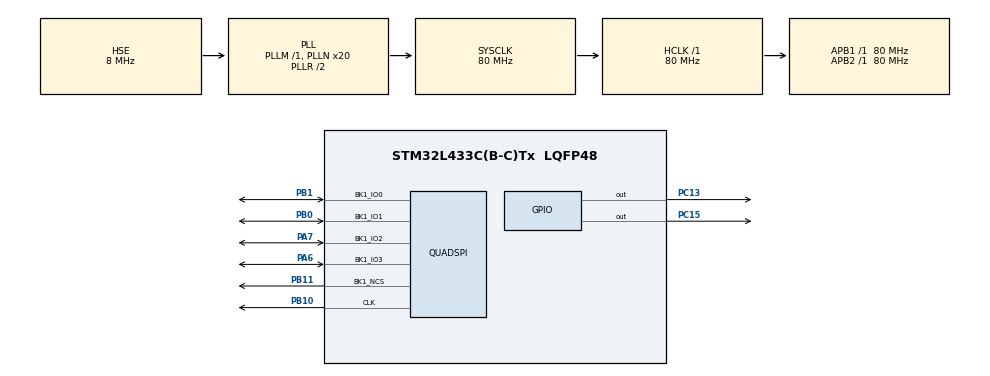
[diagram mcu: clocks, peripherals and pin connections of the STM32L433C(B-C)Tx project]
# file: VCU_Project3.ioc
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Mcu.Family=STM32L4
Mcu.Name=STM32L433C(B-C)Tx
Mcu.Package=LQFP48
NVIC.PriorityGroup=NVIC_PRIORITYGROUP_4
NVIC.QUADSPI_IRQn=true\:0\:0\:false\:false\:true
PA13\ (JTMS-SWDIO).Mode=Trace_Asynchronous_SW
PA13\ (JTMS-SWDIO).Signal=SYS_JTMS-SWDIO
PA14\ (JTCK-SWCLK).Mode=Trace_Asynchronous_SW
PA14\ (JTCK-SWCLK).Signal=SYS_JTCK-SWCLK
PA6.Mode=Single Bank 1
PA6.Signal=QUADSPI_BK1_IO3
PA7.Mode=Single Bank 1
PA7.Signal=QUADSPI_BK1_IO2
PB0.Mode=Single Bank 1
PB0.Signal=QUADSPI_BK1_IO1
PB1.Mode=Single Bank 1
PB1.Signal=QUADSPI_BK1_IO0
PB10.Mode=Single Bank 1
PB10.Signal=QUADSPI_CLK
PB11.Mode=Single Bank 1
PB11.Signal=QUADSPI_BK1_NCS
PB3\ (JTDO-TRACESWO).Mode=Trace_Asynchronous_SW
PB3\ (JTDO-TRACESWO).Signal=SYS_JTDO-SWO
PC13.Signal=GPIO_Output
PC15-OSC32_OUT\ (PC15).Signal=GPIO_Output
PH0-OSC_IN\ (PH0).Mode=HSE-External-Clock-Source
PH0-OSC_IN\ (PH0).Signal=RCC_OSC_IN
ProjectManager.HeapSize=0x200
ProjectManager.StackSize=0x400
ProjectManager.TargetToolchain=MDK-ARM V5
QUADSPI.ClockPrescaler=1
QUADSPI.FlashSize=23
RCC.ADCFreq_Value=32000000
RCC.AHBFreq_Value=80000000
RCC.APB1Freq_Value=80000000
RCC.APB1TimFreq_Value=80000000
RCC.APB2Freq_Value=80000000
RCC.APB2TimFreq_Value=80000000
RCC.CortexFreq_Value=80000000
RCC.HCLKFreq_Value=80000000
RCC.HSE_VALUE=8000000
RCC.HSI48_VALUE=48000000
RCC.HSI_VALUE=16000000
RCC.LSE_VALUE=32768
RCC.MSI_VALUE=4000000
RCC.PLLN=20
RCC.PLLSourceVirtual=RCC_PLLSOURCE_HSE
RCC.SYSCLKFreq_VALUE=80000000
RCC.SYSCLKSource=RCC_SYSCLKSOURCE_PLLCLK
RCC.USBFreq_Value=32000000
RCC.VCOOutputFreq_Value=160000000
VP_CRC_VS_CRC.Mode=CRC_Activate
VP_RNG_VS_RNG.Mode=RNG_Activate
board=VCU_Project3

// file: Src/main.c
/**
  ******************************************************************************
  * File Name          : main.c
  * Description        : Main program body
  ******************************************************************************
  *
  * COPYRIGHT(c) 2017 STMicroelectronics
  *
  * Redistribution and use in source and binary forms, with or without modification,
  * are permitted provided that the following conditions are met:
  *   1. Redistributions of source code must retain the above copyright notice,
  *      this list of conditions and the following disclaimer.
  *   2. Redistributions in binary form must reproduce the above copyright notice,
  *      this list of conditions and the following disclaimer in the documentation
  *      and/or other materials provided with the distribution.
  *   3. Neither the name of STMicroelectronics nor the names of its contributors
  *      may be used to endorse or promote products derived from this software
  *      without specific prior written permission.
  *
  * THIS SOFTWARE IS PROVIDED BY THE COPYRIGHT HOLDERS AND CONTRIBUTORS "AS IS"
  * AND ANY EXPRESS OR IMPLIED WARRANTIES, INCLUDING, BUT NOT LIMITED TO, THE
  * IMPLIED WARRANTIES OF MERCHANTABILITY AND FITNESS FOR A PARTICULAR PURPOSE ARE
  * DISCLAIMED. IN NO EVENT SHALL THE COPYRIGHT HOLDER OR CONTRIBUTORS BE LIABLE
  * FOR ANY DIRECT, INDIRECT, INCIDENTAL, SPECIAL, EXEMPLARY, OR CONSEQUENTIAL
  * DAMAGES (INCLUDING, BUT NOT LIMITED TO, PROCUREMENT OF SUBSTITUTE GOODS OR
  * SERVICES; LOSS OF USE, DATA, OR PROFITS; OR BUSINESS INTERRUPTION) HOWEVER
  * CAUSED AND ON ANY THEORY OF LIABILITY, WHETHER IN CONTRACT, STRICT LIABILITY,
  * OR TORT (INCLUDING NEGLIGENCE OR OTHERWISE) ARISING IN ANY WAY OUT OF THE USE
  * OF THIS SOFTWARE, EVEN IF ADVISED OF THE POSSIBILITY OF SUCH DAMAGE.
  *
  ******************************************************************************
  */
#include "main.h"
#include "stm32l4xx_hal.h"
#include "crc.h"
#include "quadspi.h"
#include "rng.h"
#include "gpio.h"

/* USER CODE BEGIN PV */
/* Private variables ---------------------------------------------------------*/

/* USER CODE END PV */

void SystemClock_Config(void);
void Error_Handler(void);

/* USER CODE BEGIN PFP */
/* Private function prototypes -----------------------------------------------*/

/* USER CODE END PFP */

int main(void)
{

  /* USER CODE BEGIN 1 */
  uint8_t dummyVariable[] = "VCU_Project3";

  /* USER CODE END 1 */

  /* MCU Configuration----------------------------------------------------------*/

  /* Reset of all peripherals, Initializes the Flash interface and the Systick. */
  HAL_Init();

  /* Configure the system clock */
  SystemClock_Config();

  /* Initialize all configured peripherals */
  MX_GPIO_Init();
  MX_QUADSPI_Init();
  MX_CRC_Init();
  MX_RNG_Init();

  /* USER CODE BEGIN 2 */
  dummyVariable[0] = 0;

  /* USER CODE END 2 */

  /* Infinite loop */
  while (1)
  {

  }

}

/** System Clock Configuration
*/
void SystemClock_Config(void)
{

  RCC_OscInitTypeDef RCC_OscInitStruct;
  RCC_ClkInitTypeDef RCC_ClkInitStruct;
  RCC_PeriphCLKInitTypeDef PeriphClkInit;

    /**Initializes the CPU, AHB and APB busses clocks
    */
  RCC_OscInitStruct.OscillatorType = RCC_OSCILLATORTYPE_HSE;
  RCC_OscInitStruct.HSEState = RCC_HSE_BYPASS;
  RCC_OscInitStruct.PLL.PLLState = RCC_PLL_ON;
  RCC_OscInitStruct.PLL.PLLSource = RCC_PLLSOURCE_HSE;
  RCC_OscInitStruct.PLL.PLLM = 1;
  RCC_OscInitStruct.PLL.PLLN = 20;
  RCC_OscInitStruct.PLL.PLLP = RCC_PLLP_DIV7;
  RCC_OscInitStruct.PLL.PLLQ = RCC_PLLQ_DIV2;
  RCC_OscInitStruct.PLL.PLLR = RCC_PLLR_DIV2;
  if (HAL_RCC_OscConfig(&RCC_OscInitStruct) != HAL_OK)
  {
    Error_Handler();
  }

    /**Initializes the CPU, AHB and APB busses clocks
    */
  RCC_ClkInitStruct.ClockType = RCC_CLOCKTYPE_HCLK|RCC_CLOCKTYPE_SYSCLK
                              |RCC_CLOCKTYPE_PCLK1|RCC_CLOCKTYPE_PCLK2;
  RCC_ClkInitStruct.SYSCLKSource = RCC_SYSCLKSOURCE_PLLCLK;
  RCC_ClkInitStruct.AHBCLKDivider = RCC_SYSCLK_DIV1;
  RCC_ClkInitStruct.APB1CLKDivider = RCC_HCLK_DIV1;
  RCC_ClkInitStruct.APB2CLKDivider = RCC_HCLK_DIV1;

  if (HAL_RCC_ClockConfig(&RCC_ClkInitStruct, FLASH_LATENCY_4) != HAL_OK)
  {
    Error_Handler();
  }

  PeriphClkInit.PeriphClockSelection = RCC_PERIPHCLK_RNG;
  PeriphClkInit.RngClockSelection = RCC_RNGCLKSOURCE_PLLSAI1;
  PeriphClkInit.PLLSAI1.PLLSAI1Source = RCC_PLLSOURCE_HSE;
  PeriphClkInit.PLLSAI1.PLLSAI1M = 1;
  PeriphClkInit.PLLSAI1.PLLSAI1N = 8;
  PeriphClkInit.PLLSAI1.PLLSAI1P = RCC_PLLP_DIV7;
  PeriphClkInit.PLLSAI1.PLLSAI1Q = RCC_PLLQ_DIV2;
  PeriphClkInit.PLLSAI1.PLLSAI1R = RCC_PLLR_DIV2;
  PeriphClkInit.PLLSAI1.PLLSAI1ClockOut = RCC_PLLSAI1_48M2CLK;
  if (HAL_RCCEx_PeriphCLKConfig(&PeriphClkInit) != HAL_OK)
  {
    Error_Handler();
  }

    /**Configure the main internal regulator output voltage
    */
  if (HAL_PWREx_ControlVoltageScaling(PWR_REGULATOR_VOLTAGE_SCALE1) != HAL_OK)
  {
    Error_Handler();
  }

    /**Configure the Systick interrupt time
    */
  HAL_SYSTICK_Config(HAL_RCC_GetHCLKFreq()/1000);

    /**Configure the Systick
    */
  HAL_SYSTICK_CLKSourceConfig(SYSTICK_CLKSOURCE_HCLK);

  /* SysTick_IRQn interrupt configuration */
  HAL_NVIC_SetPriority(SysTick_IRQn, 0, 0);
}

void Error_Handler(void)
{
  while(1)
  {
  }
}

/************************ (C) COPYRIGHT STMicroelectronics *****END OF FILE****/
